VERSION "10.8"

NS_ :

BS_:

BU_:
VAL_TABLE_ Value_Table_Track_Status 7 "New Coasting Target" 6 "Invalid Coasting Target" 5 "Merged Target" 4 "Coasting Target" 3 "Updated Target" 2 "New Updated Target" 1 "New Target" 0 "No Target" ;

BO_ 1571 from_control_team: 8 Vector__XXX
 SG_ lane_change_info : 8|2@1+ (1,0) [0|3] "" Vector__XXX
 SG_ speed_limit : 0|8@1+ (1,0) [0|120] "kph" Vector__XXX

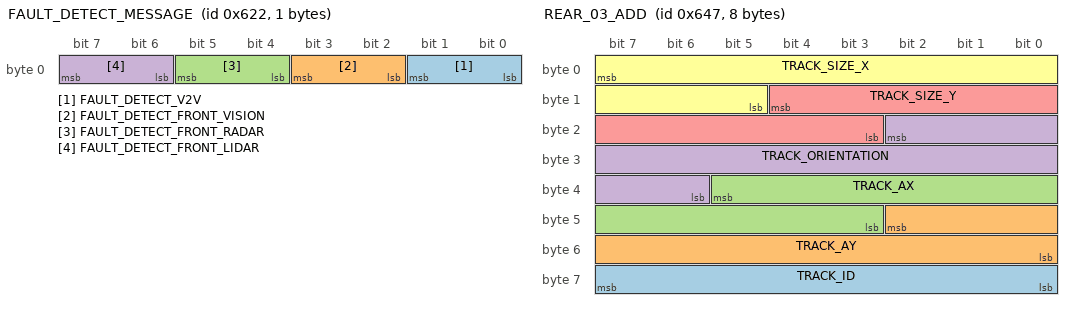
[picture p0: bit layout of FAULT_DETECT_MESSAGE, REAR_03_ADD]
BO_ 1570 FAULT_DETECT_MESSAGE: 1 Vector__XXX
 SG_ FAULT_DETECT_V2V : 1|2@0+ (1,0) [0|0] "" Vector__XXX
 SG_ FAULT_DETECT_FRONT_VISION : 3|2@0+ (1,0) [0|0] "" Vector__XXX
 SG_ FAULT_DETECT_FRONT_RADAR : 5|2@0+ (1,0) [0|0] "" Vector__XXX
 SG_ FAULT_DETECT_FRONT_LIDAR : 7|2@0+ (1,0) [0|0] "" Vector__XXX

BO_ 1607 REAR_03_ADD: 8 Vector__XXX
 SG_ TRACK_ID : 63|8@0+ (1,0) [0|255] "" Vector__XXX
 SG_ TRACK_AY : 42|11@0- (0.01,0) [-10.24|10.23] "m/s^2" Vector__XXX
 SG_ TRACK_AX : 37|11@0- (0.01,0) [-10.24|10.23] "m/s^2" Vector__XXX
 SG_ TRACK_ORIENTATION : 18|13@0- (0.002,0) [-8.192|8.19] "rad" Vector__XXX
 SG_ TRACK_SIZE_Y : 12|10@0+ (0.01,0) [0|10.23] "m" Vector__XXX
 SG_ TRACK_SIZE_X : 7|11@0+ (0.01,0) [0|20.47] "m" Vector__XXX

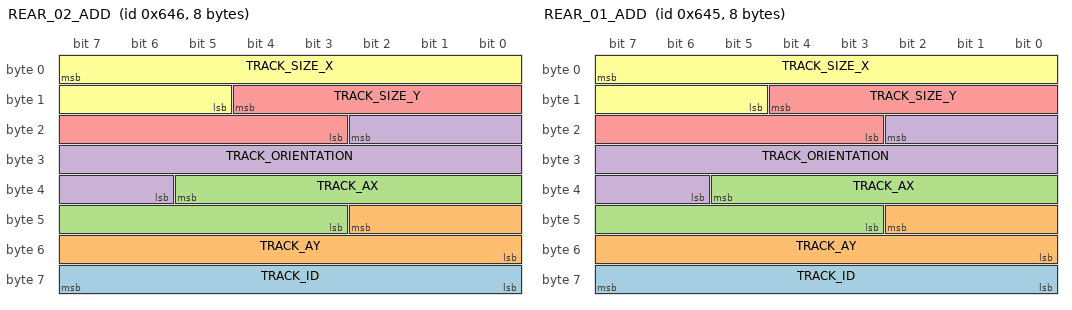
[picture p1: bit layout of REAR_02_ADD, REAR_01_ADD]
BO_ 1606 REAR_02_ADD: 8 Vector__XXX
 SG_ TRACK_ID : 63|8@0+ (1,0) [0|255] "" Vector__XXX
 SG_ TRACK_AY : 42|11@0- (0.01,0) [-10.24|10.23] "m/s^2" Vector__XXX
 SG_ TRACK_AX : 37|11@0- (0.01,0) [-10.24|10.23] "m/s^2" Vector__XXX
 SG_ TRACK_ORIENTATION : 18|13@0- (0.002,0) [-8.192|8.19] "rad" Vector__XXX
 SG_ TRACK_SIZE_Y : 12|10@0+ (0.01,0) [0|10.23] "m" Vector__XXX
 SG_ TRACK_SIZE_X : 7|11@0+ (0.01,0) [0|20.47] "m" Vector__XXX

BO_ 1605 REAR_01_ADD: 8 Vector__XXX
 SG_ TRACK_ID : 63|8@0+ (1,0) [0|255] "" Vector__XXX
 SG_ TRACK_AY : 42|11@0- (0.01,0) [-10.24|10.23] "m/s^2" Vector__XXX
 SG_ TRACK_AX : 37|11@0- (0.01,0) [-10.24|10.23] "m/s^2" Vector__XXX
 SG_ TRACK_ORIENTATION : 18|13@0- (0.002,0) [-8.192|8.19] "rad" Vector__XXX
 SG_ TRACK_SIZE_Y : 12|10@0+ (0.01,0) [0|10.23] "m" Vector__XXX
 SG_ TRACK_SIZE_X : 7|11@0+ (0.01,0) [0|20.47] "m" Vector__XXX

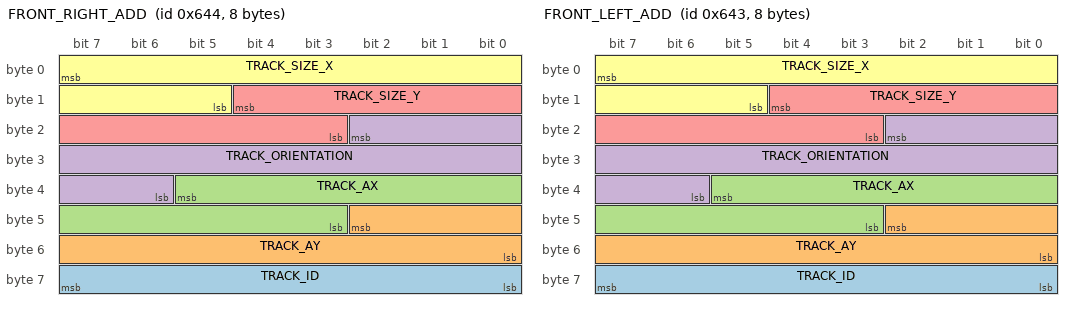
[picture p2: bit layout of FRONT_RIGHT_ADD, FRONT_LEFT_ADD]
BO_ 1604 FRONT_RIGHT_ADD: 8 Vector__XXX
 SG_ TRACK_ID : 63|8@0+ (1,0) [0|255] "" Vector__XXX
 SG_ TRACK_AY : 42|11@0- (0.01,0) [-10.24|10.23] "m/s^2" Vector__XXX
 SG_ TRACK_AX : 37|11@0- (0.01,0) [-10.24|10.23] "m/s^2" Vector__XXX
 SG_ TRACK_ORIENTATION : 18|13@0- (0.002,0) [-8.192|8.19] "rad" Vector__XXX
 SG_ TRACK_SIZE_Y : 12|10@0+ (0.01,0) [0|10.23] "m" Vector__XXX
 SG_ TRACK_SIZE_X : 7|11@0+ (0.01,0) [0|20.47] "m" Vector__XXX

BO_ 1603 FRONT_LEFT_ADD: 8 Vector__XXX
 SG_ TRACK_ID : 63|8@0+ (1,0) [0|255] "" Vector__XXX
 SG_ TRACK_AY : 42|11@0- (0.01,0) [-10.24|10.23] "m/s^2" Vector__XXX
 SG_ TRACK_AX : 37|11@0- (0.01,0) [-10.24|10.23] "m/s^2" Vector__XXX
 SG_ TRACK_ORIENTATION : 18|13@0- (0.002,0) [-8.192|8.19] "rad" Vector__XXX
 SG_ TRACK_SIZE_Y : 12|10@0+ (0.01,0) [0|10.23] "m" Vector__XXX
 SG_ TRACK_SIZE_X : 7|11@0+ (0.01,0) [0|20.47] "m" Vector__XXX

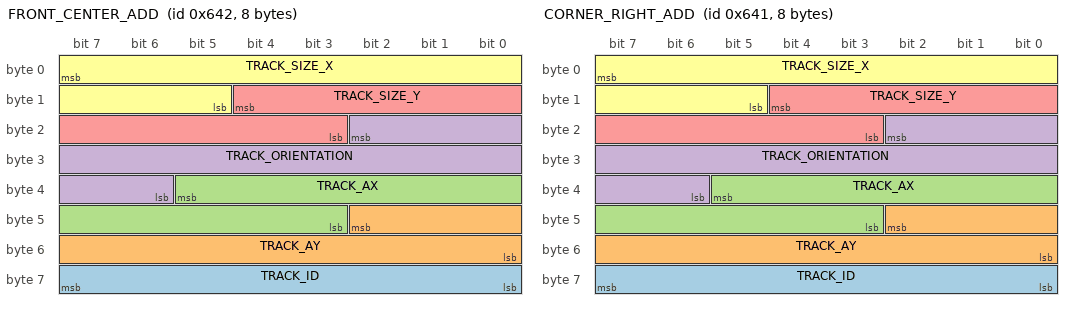
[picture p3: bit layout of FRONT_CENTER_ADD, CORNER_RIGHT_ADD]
BO_ 1602 FRONT_CENTER_ADD: 8 Vector__XXX
 SG_ TRACK_ID : 63|8@0+ (1,0) [0|255] "" Vector__XXX
 SG_ TRACK_AY : 42|11@0- (0.01,0) [-10.24|10.23] "m/s^2" Vector__XXX
 SG_ TRACK_AX : 37|11@0- (0.01,0) [-10.24|10.23] "m/s^2" Vector__XXX
 SG_ TRACK_ORIENTATION : 18|13@0- (0.002,0) [-8.192|8.19] "rad" Vector__XXX
 SG_ TRACK_SIZE_Y : 12|10@0+ (0.01,0) [0|10.23] "m" Vector__XXX
 SG_ TRACK_SIZE_X : 7|11@0+ (0.01,0) [0|20.47] "m" Vector__XXX

BO_ 1601 CORNER_RIGHT_ADD: 8 Vector__XXX
 SG_ TRACK_ID : 63|8@0+ (1,0) [0|255] "" Vector__XXX
 SG_ TRACK_AY : 42|11@0- (0.01,0) [-10.24|10.23] "m/s^2" Vector__XXX
 SG_ TRACK_AX : 37|11@0- (0.01,0) [-10.24|10.23] "m/s^2" Vector__XXX
 SG_ TRACK_ORIENTATION : 18|13@0- (0.002,0) [-8.192|8.19] "rad" Vector__XXX
 SG_ TRACK_SIZE_Y : 12|10@0+ (0.01,0) [0|10.23] "m" Vector__XXX
 SG_ TRACK_SIZE_X : 7|11@0+ (0.01,0) [0|20.47] "m" Vector__XXX

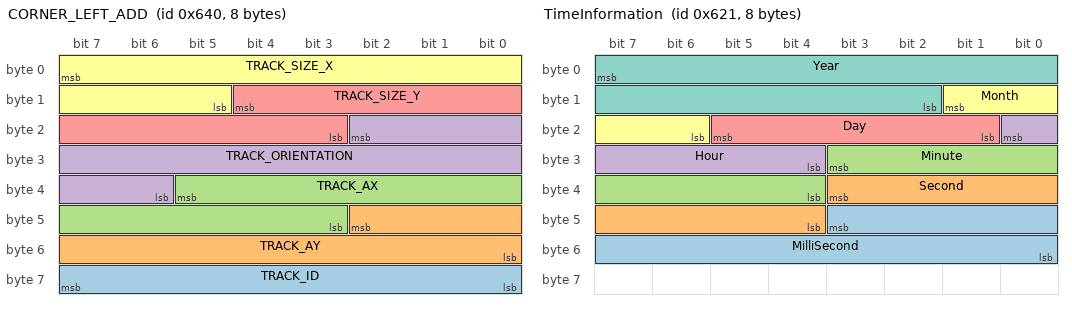
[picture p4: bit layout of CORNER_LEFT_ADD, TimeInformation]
BO_ 1600 CORNER_LEFT_ADD: 8 Vector__XXX
 SG_ TRACK_ID : 63|8@0+ (1,0) [0|255] "" Vector__XXX
 SG_ TRACK_AY : 42|11@0- (0.01,0) [-10.24|10.23] "m/s^2" Vector__XXX
 SG_ TRACK_AX : 37|11@0- (0.01,0) [-10.24|10.23] "m/s^2" Vector__XXX
 SG_ TRACK_ORIENTATION : 18|13@0- (0.002,0) [-8.192|8.19] "rad" Vector__XXX
 SG_ TRACK_SIZE_Y : 12|10@0+ (0.01,0) [0|10.23] "m" Vector__XXX
 SG_ TRACK_SIZE_X : 7|11@0+ (0.01,0) [0|20.47] "m" Vector__XXX

BO_ 1569 TimeInformation: 8 Vector__XXX
 SG_ MilliSecond : 43|12@0+ (1,0) [0|0] "" Vector__XXX
 SG_ Second : 35|8@0+ (1,0) [0|0] "" Vector__XXX
 SG_ Minute : 27|8@0+ (1,0) [0|0] "" Vector__XXX
 SG_ Hour : 16|5@0+ (1,0) [0|0] "" Vector__XXX
 SG_ Day : 21|5@0+ (1,0) [0|0] "" Vector__XXX
 SG_ Month : 9|4@0+ (1,0) [0|0] "" Vector__XXX
 SG_ Year : 7|14@0+ (1,0) [0|0] "" Vector__XXX

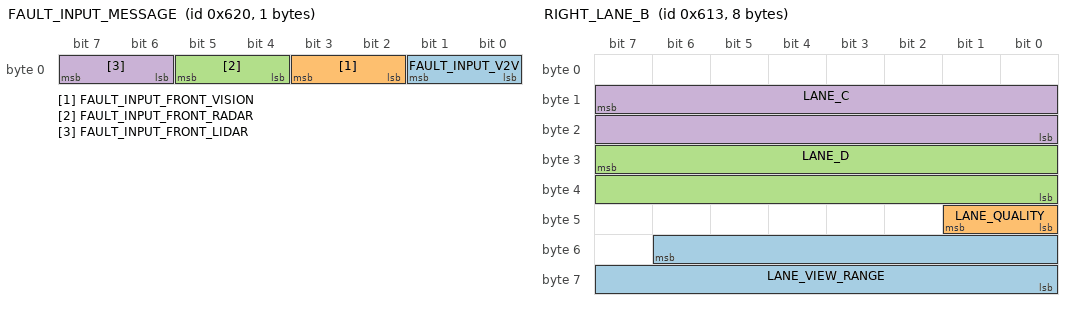
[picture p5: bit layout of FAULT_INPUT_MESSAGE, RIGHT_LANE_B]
BO_ 1568 FAULT_INPUT_MESSAGE: 1 Vector__XXX
 SG_ FAULT_INPUT_V2V : 1|2@0+ (1,0) [0|0] "" Vector__XXX
 SG_ FAULT_INPUT_FRONT_VISION : 3|2@0+ (1,0) [0|0] "" Vector__XXX
 SG_ FAULT_INPUT_FRONT_RADAR : 5|2@0+ (1,0) [0|0] "" Vector__XXX
 SG_ FAULT_INPUT_FRONT_LIDAR : 7|2@0+ (1,0) [0|0] "" Vector__XXX

BO_ 1555 RIGHT_LANE_B: 8 Vector__XXX
 SG_ LANE_VIEW_RANGE : 54|15@0+ (0.00390625,0) [0|0] "" Vector__XXX
 SG_ LANE_QUALITY : 41|2@0+ (1,0) [0|0] "" Vector__XXX
 SG_ LANE_D : 31|16@0- (0.00390625,0) [0|0] "" Vector__XXX
 SG_ LANE_C : 15|16@0+ (1.52588E-005,-0.5) [0|0] "" Vector__XXX

BO_ 1554 RIGHT_LANE_A: 8 Vector__XXX
 SG_ LANE_B : 39|32@0+ (2.3283064E-010,-0.5) [0|0] "1/Meters" Vector__XXX
 SG_ LANE_A : 7|32@0+ (1.45519E-011,-0.03125) [0|0] "1/Meters^2" Vector__XXX

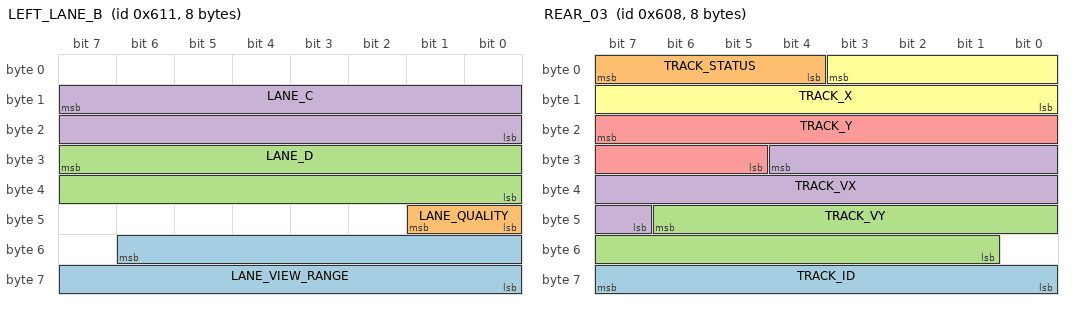
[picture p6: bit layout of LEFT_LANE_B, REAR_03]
BO_ 1553 LEFT_LANE_B: 8 Vector__XXX
 SG_ LANE_VIEW_RANGE : 54|15@0+ (0.00390625,0) [0|0] "" Vector__XXX
 SG_ LANE_QUALITY : 41|2@0+ (1,0) [0|0] "" Vector__XXX
 SG_ LANE_D : 31|16@0- (0.00390625,0) [0|0] "" Vector__XXX
 SG_ LANE_C : 15|16@0+ (1.52588E-005,-0.5) [0|0] "" Vector__XXX

BO_ 1552 LEFT_LANE_A: 8 Vector__XXX
 SG_ LANE_B : 39|32@0+ (2.3283064E-010,-0.5) [0|0] "1/Meters" Vector__XXX
 SG_ LANE_A : 7|32@0+ (1.45519E-011,-0.03125) [0|0] "1/Meters^2" Vector__XXX

BO_ 1544 REAR_03: 8 Vector__XXX
 SG_ TRACK_ID : 63|8@0+ (1,0) [0|0] "" Vector__XXX
 SG_ TRACK_STATUS : 7|4@0+ (1,0) [0|0] "" Vector__XXX
 SG_ TRACK_VY : 46|14@0- (0.01,0) [-81.92|81.91] "m/s" Vector__XXX
 SG_ TRACK_VX : 28|14@0- (0.01,0) [-81.92|81.91] "m/s" Vector__XXX
 SG_ TRACK_Y : 23|11@0- (0.04,0) [-40.9|40.9] "m" Vector__XXX
 SG_ TRACK_X : 3|12@0- (0.1,0) [-204.8|204.7] "m" Vector__XXX

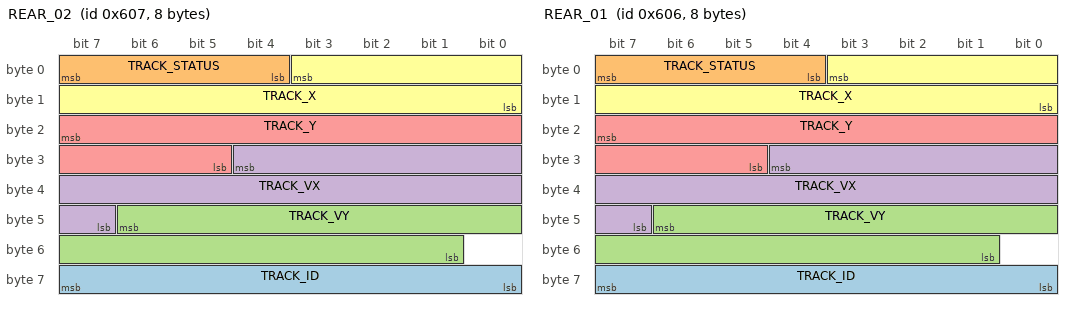
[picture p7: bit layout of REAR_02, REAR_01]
BO_ 1543 REAR_02: 8 Vector__XXX
 SG_ TRACK_ID : 63|8@0+ (1,0) [0|0] "" Vector__XXX
 SG_ TRACK_STATUS : 7|4@0+ (1,0) [0|0] "" Vector__XXX
 SG_ TRACK_VY : 46|14@0- (0.01,0) [-81.92|81.91] "m/s" Vector__XXX
 SG_ TRACK_VX : 28|14@0- (0.01,0) [-81.92|81.91] "m/s" Vector__XXX
 SG_ TRACK_Y : 23|11@0- (0.04,0) [-40.9|40.9] "m" Vector__XXX
 SG_ TRACK_X : 3|12@0- (0.1,0) [-204.8|204.7] "m" Vector__XXX

BO_ 1542 REAR_01: 8 Vector__XXX
 SG_ TRACK_ID : 63|8@0+ (1,0) [0|0] "" Vector__XXX
 SG_ TRACK_STATUS : 7|4@0+ (1,0) [0|0] "" Vector__XXX
 SG_ TRACK_VY : 46|14@0- (0.01,0) [-81.92|81.91] "m/s" Vector__XXX
 SG_ TRACK_VX : 28|14@0- (0.01,0) [-81.92|81.91] "m/s" Vector__XXX
 SG_ TRACK_Y : 23|11@0- (0.04,0) [-40.9|40.9] "m" Vector__XXX
 SG_ TRACK_X : 3|12@0- (0.1,0) [-204.8|204.7] "m" Vector__XXX

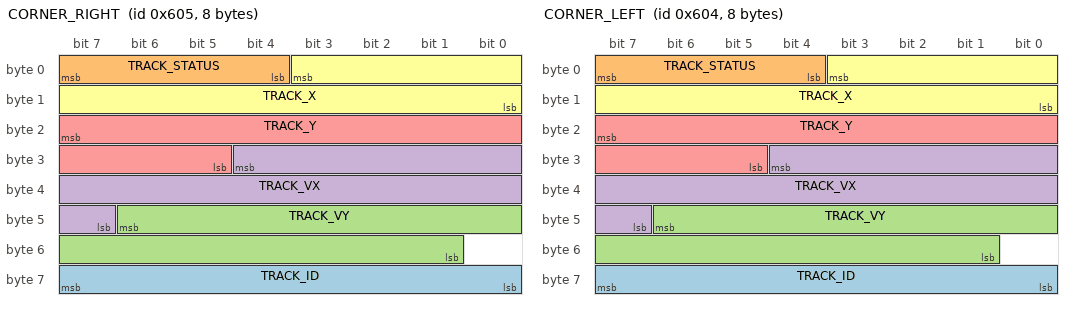
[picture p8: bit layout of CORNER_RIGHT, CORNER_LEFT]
BO_ 1541 CORNER_RIGHT: 8 Vector__XXX
 SG_ TRACK_ID : 63|8@0+ (1,0) [0|0] "" Vector__XXX
 SG_ TRACK_STATUS : 7|4@0+ (1,0) [0|0] "" Vector__XXX
 SG_ TRACK_VY : 46|14@0- (0.01,0) [-81.92|81.91] "m/s" Vector__XXX
 SG_ TRACK_VX : 28|14@0- (0.01,0) [-81.92|81.91] "m/s" Vector__XXX
 SG_ TRACK_Y : 23|11@0- (0.04,0) [-40.9|40.9] "m" Vector__XXX
 SG_ TRACK_X : 3|12@0- (0.1,0) [-204.8|204.7] "m" Vector__XXX

BO_ 1540 CORNER_LEFT: 8 Vector__XXX
 SG_ TRACK_ID : 63|8@0+ (1,0) [0|0] "" Vector__XXX
 SG_ TRACK_STATUS : 7|4@0+ (1,0) [0|0] "" Vector__XXX
 SG_ TRACK_VY : 46|14@0- (0.01,0) [-81.92|81.91] "m/s" Vector__XXX
 SG_ TRACK_VX : 28|14@0- (0.01,0) [-81.92|81.91] "m/s" Vector__XXX
 SG_ TRACK_Y : 23|11@0- (0.04,0) [-40.9|40.9] "m" Vector__XXX
 SG_ TRACK_X : 3|12@0- (0.1,0) [-204.8|204.7] "m" Vector__XXX

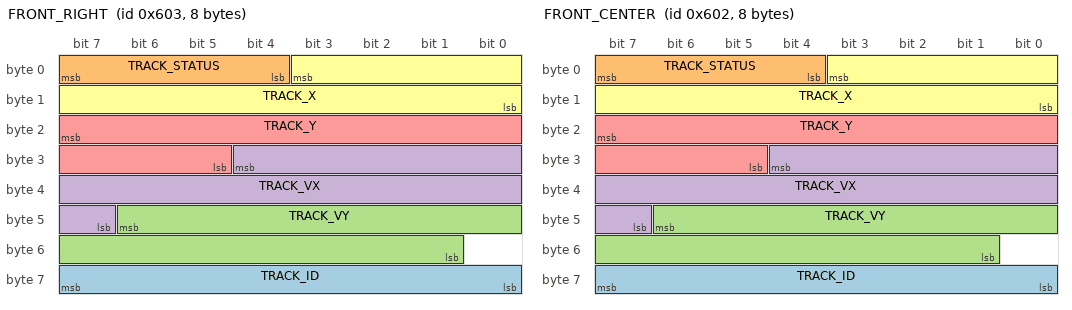
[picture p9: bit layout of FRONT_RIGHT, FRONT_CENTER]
BO_ 1539 FRONT_RIGHT: 8 Vector__XXX
 SG_ TRACK_ID : 63|8@0+ (1,0) [0|0] "" Vector__XXX
 SG_ TRACK_STATUS : 7|4@0+ (1,0) [0|0] "" Vector__XXX
 SG_ TRACK_VY : 46|14@0- (0.01,0) [-81.92|81.91] "m/s" Vector__XXX
 SG_ TRACK_VX : 28|14@0- (0.01,0) [-81.92|81.91] "m/s" Vector__XXX
 SG_ TRACK_Y : 23|11@0- (0.04,0) [-40.9|40.9] "m" Vector__XXX
 SG_ TRACK_X : 3|12@0- (0.1,0) [-204.8|204.7] "m" Vector__XXX

BO_ 1538 FRONT_CENTER: 8 Vector__XXX
 SG_ TRACK_ID : 63|8@0+ (1,0) [0|0] "" Vector__XXX
 SG_ TRACK_STATUS : 7|4@0+ (1,0) [0|0] "" Vector__XXX
 SG_ TRACK_VY : 46|14@0- (0.01,0) [-81.92|81.91] "m/s" Vector__XXX
 SG_ TRACK_VX : 28|14@0- (0.01,0) [-81.92|81.91] "m/s" Vector__XXX
 SG_ TRACK_Y : 23|11@0- (0.04,0) [-40.9|40.9] "m" Vector__XXX
 SG_ TRACK_X : 3|12@0- (0.1,0) [-204.8|204.7] "m" Vector__XXX

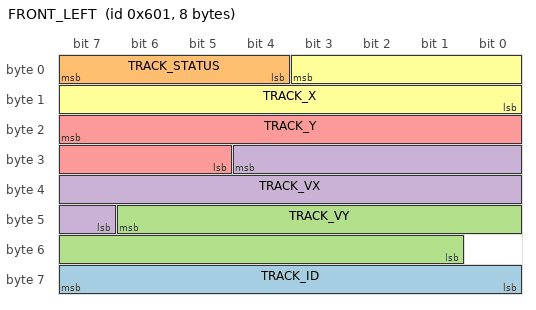
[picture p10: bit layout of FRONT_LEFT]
BO_ 1537 FRONT_LEFT: 8 Vector__XXX
 SG_ TRACK_ID : 63|8@0+ (1,0) [0|0] "" Vector__XXX
 SG_ TRACK_STATUS : 7|4@0+ (1,0) [0|0] "" Vector__XXX
 SG_ TRACK_VY : 46|14@0- (0.01,0) [-81.92|81.91] "m/s" Vector__XXX
 SG_ TRACK_VX : 28|14@0- (0.01,0) [-81.92|81.91] "m/s" Vector__XXX
 SG_ TRACK_Y : 23|11@0- (0.04,0) [-40.9|40.9] "m" Vector__XXX
 SG_ TRACK_X : 3|12@0- (0.1,0) [-204.8|204.7] "m" Vector__XXX

BA_DEF_ SG_  "GenSigSendType" ENUM  "Cyclic","OnWrite","OnWriteWithRepetition","OnChange","OnChangeWithRepetition","IfActive","IfActiveWithRepetition","NoSigSendType";
BA_DEF_ BO_  "GenMsgILSupport" ENUM  "No","Yes";
BA_DEF_ BO_  "GenMsgCycleTime" INT 2 50000;
BA_DEF_ BO_  "GenMsgDelayTime" INT 1 1000;
BA_DEF_ BO_  "GenMsgNrOfRepetitions" INT 1 999999;
BA_DEF_ BO_  "GenMsgSendType" ENUM  "Cyclic","not_used","not_used","not_used","not_used","not_used","not_used","IfActive","NoMsgSendType";
BA_DEF_ BU_  "ILUsed" ENUM  "No","Yes";
BA_DEF_  "DBName" STRING ;
BA_DEF_  "Baudrate" INT 50000 1000000;
BA_DEF_  "BusType" STRING ;
BA_DEF_  "Manufacturer" STRING ;
BA_DEF_REL_ BU_SG_REL_  "GenSigTimeoutTime" INT 0 5000;
BA_DEF_DEF_  "GenSigSendType" "Cyclic";
BA_DEF_DEF_  "GenMsgILSupport" "Yes";
BA_DEF_DEF_  "GenMsgCycleTime" 50;
BA_DEF_DEF_  "GenMsgDelayTime" 10;
BA_DEF_DEF_  "GenMsgNrOfRepetitions" 3;
BA_DEF_DEF_  "GenMsgSendType" "Cyclic";
BA_DEF_DEF_  "ILUsed" "Yes";
BA_DEF_DEF_  "DBName" "";
BA_DEF_DEF_  "Baudrate" 500000;
BA_DEF_DEF_  "BusType" "CAN";
BA_DEF_DEF_  "Manufacturer" "Geely";
BA_DEF_DEF_REL_ "GenSigTimeoutTime" 500;
BA_ "DBName" "SENSOR_FUSION_revised";
